# ESP32-S31 register map
Vendor: ESPRESSIF SYSTEMS (SHANGHAI) CO., LTD.; Series: ESP32 S-Series; File version: 1
CPU: RV32IMAFC r0p0, little endian, no MPU, FPU, 0 interrupt priority bits
Address unit: 32 bits
Registers are 32-bit, read-write, reset 0x0 unless marked. A register's access mark holds for its fields unless they carry their own. Offsets are from the block's base; [hi:lo] are bit positions; {n}, {i} and the like mark numbered series; <NAME> marks a mode.

## ECC — ECC (ECC Hardware Accelerator)
Base 0x2050B000
0x0C MULT_INT_RAW ro — ECC raw interrupt status register
  [0] MULT_CALC_DONE_INT_RAW — The raw interrupt status of the ECC_CALC_DONE_INT interrupt.
0x10 MULT_INT_ST ro — ECC masked interrupt status register
  [0] MULT_CALC_DONE_INT_ST — The masked interrupt status of the ECC_CALC_DONE_INT interrupt.
0x14 MULT_INT_ENA — ECC interrupt enable register
  [0] MULT_CALC_DONE_INT_ENA — Write 1 to enable the ECC_CALC_DONE_INT interrupt.
0x18 MULT_INT_CLR wo — ECC interrupt clear register
  [0] MULT_CALC_DONE_INT_CLR — Write 1 to clear the ECC_CALC_DONE_INT interrupt.
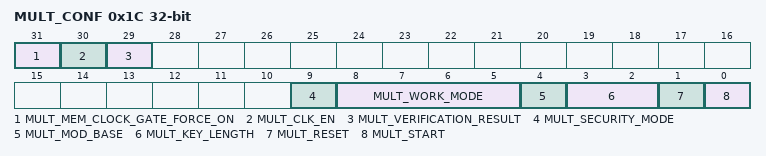
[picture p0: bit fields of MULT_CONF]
0x1C MULT_CONF access per field — ECC configuration register
  [31] MULT_MEM_CLOCK_GATE_FORCE_ON rw — Configures whether to force on ECC memory clock gate. \\ 0: No effect\\ 1: Force on\\
  [30] MULT_CLK_EN rw — Configures whether to force on register clock gate. \\ 0: No effect\\ 1: Force on\\
  [29] MULT_VERIFICATION_RESULT ro — Represents the verification result of ECC Accelerator, valid only when calculation is done.
  [9] MULT_SECURITY_MODE rw — Configures the security mode of ECC Accelerator.\\ 0: no secure function enabled.\\ 1: enable constant-time calculation in all point multiplication modes.\\
  [8:5] MULT_WORK_MODE rw — Configures the work mode of ECC Accelerator.\\ 0: Point Multi mode\\ 1: Reserved\\ 2: Point Verif mode\\ 3: Point Verif + Multi mode\\ 4: Jacobian Point Multi mode\\ 5: Reserved\\ 6: Jacobian Point Verif mode\\ 7: Point Verif + Jacobian Point Multi mode\\ 8: Mod Add mode\\ 9. Mod Sub mode\\ 10: Mod Multi mode\\ 11: Mod Div mode\\
  [4] MULT_MOD_BASE rw — Configures the mod base of mod operation, only valid in work_mode 8-11. \\ 0: n(order of curve)\\ 1: p(mod base of curve)\\
  [3:2] MULT_KEY_LENGTH rw — Configures the key length mode bit of ECC Accelerator. \\ 0: P-192\\ 1: P-256\\ 2: P-384\\ 3: SM2.\\
  [1] MULT_RESET wo — Configures whether to reset ECC Accelerator. \\ 0: No effect\\ 1: Reset\\
  [0] MULT_START rw — Configures whether to start calculation of ECC Accelerator. This bit will be self-cleared after the calculation is done. \\ 0: No effect\\ 1: Start calculation of ECC Accelerator\\
0x20 MULT_FREE reset 0x1 — ECC free status register
  [0] MULT_FREE — ECC mult free state register \\ 0: non-free \\ 1: free \\
0xFC MULT_DATE reset 0x2506190 — Version control register
  [27:0] MULT_DATE — ECC mult version control register
{0x100+i} MULT_K_MEM[{i}] (i=0..47) 8-bit access not given — The memory that stores k.
{0x130+i} MULT_PX_MEM[{i}] (i=0..47) 8-bit access not given — The memory that stores Px.
{0x160+i} MULT_PY_MEM[{i}] (i=0..47) 8-bit access not given — The memory that stores Py.
{0x190+i} MULT_QX_MEM[{i}] (i=0..47) 8-bit access not given — The memory that stores Qx.
{0x1C0+i} MULT_QY_MEM[{i}] (i=0..47) 8-bit access not given — The memory that stores Qy.
{0x1F0+i} MULT_QZ_MEM[{i}] (i=0..47) 8-bit access not given — The memory that stores Qz.

## HMAC — HMAC (Hash-based Message Authentication Code) Accelerator
Base 0x2050D000
0x40 SET_START wo — HMAC start control register
  [0] SET_START — Configures whether or not to enable HMAC. \\0: Disable HMAC \\1: Enable HMAC
0x44 SET_PARA_PURPOSE wo — HMAC parameter configuration register
  [3:0] PURPOSE_SET — Configures the HMAC purpose, refer to the Table <a href=tab:hmac-key-purpose">link</a>. "
0x48 SET_PARA_KEY wo — HMAC parameters configuration register
  [2:0] KEY_SET — Configures HMAC key. There are six keys with index 0~5. Write the index of the selected key to this field.
0x4C SET_PARA_FINISH wo — HMAC configuration completion register
  [0] SET_PARA_END — Configures whether to finish HMAC configuration. \\0: No effect \\1: Finish configuration
0x50 SET_MESSAGE_ONE wo — HMAC message control register
  [0] SET_TEXT_ONE — Calls SHA to calculate one message block.
0x54 SET_MESSAGE_ING wo — HMAC message continue register
  [0] SET_TEXT_ING — Configures whether or not there are unprocessed message blocks. \\0: No unprocessed message block \\1: There are still some message blocks to be processed.
0x58 SET_MESSAGE_END wo — HMAC message end register
  [0] SET_TEXT_END — Configures whether to start hardware padding. \\0: No effect \\1: Start hardware padding
0x5C SET_RESULT_FINISH wo — HMAC result reading finish register
  [0] SET_RESULT_END — Configures whether to exit upstream mode and clear calculation results. \\0: Not exit \\1: Exit upstream mode and clear calculation results.
0x60 SET_INVALIDATE_JTAG wo — Invalidate JTAG result register
  [0] SET_INVALIDATE_JTAG — Configures whether or not to clear calculation results when re-enabling JTAG in downstream mode. \\0: Not clear \\1: Clear calculation results
0x64 SET_INVALIDATE_DS wo — Invalidate digital signature result register
  [0] SET_INVALIDATE_DS — Configures whether or not to clear calculation results of the DS module in downstream mode. \\0: Not clear \\1: Clear calculation results
0x68 QUERY_ERROR ro — Stores matching results between keys generated by users and corresponding purposes
  [0] QUREY_CHECK — Represents whether or not an HMAC key matches the purpose. \\0: Match \\1: Error
0x6C QUERY_BUSY ro — Busy state of HMAC module
  [0] BUSY_STATE — Represents whether or not HMAC is in a busy state. Before configuring HMAC, please make sure HMAC is in an IDLE state. \\0: Idle \\1: HMAC is still working on the calculation
0x70 TIMEOUT_LIMIT reset 0xFFFFFFFF — HMAC timeout limit configurate register
  [31:0] TIMEOUT_LIMIT — The timeout limitation for waiting sub-IP.
{0x80+i} WR_MESSAGE_MEM[{i}] (i=0..63) 8-bit access not given — Message block memory.
{0xC0+i} RD_RESULT_MEM[{i}] (i=0..31) 8-bit access not given — Result from upstream.
0xF0 SET_MESSAGE_PAD wo — Software padding register
  [0] SET_TEXT_PAD — Configures whether or not the padding is applied by software. \\0: Not applied by software \\1: Applied by software
0xF4 ONE_BLOCK wo — One block message register
  [0] SET_ONE_BLOCK — Write 1 to indicate there is only one block which already contains padding bits and there is no need for padding.
0xF8 SOFT_JTAG_CTRL wo — Jtag register 0.
  [0] SOFT_JTAG_CTRL — Configures whether or not to enable JTAG authentication mode. \\0: Disable \\1: Enable \\
0xFC WR_JTAG wo — Re-enable JTAG register 1
  [31:0] WR_JTAG — Writes the comparing input used for re-enabling JTAG.
0x1FC DATE reset 0x20250819 — Version control register
  [29:0] DATE — Hmac date information/ hmac version information.
